AUTOSAR XML (schema 4-0-3)
standard types defined: UInt32, UInt8
package /AUTOSAR_Platform/DataConstrs
  range DC_UInt8: raw 0..255
package /PATAC/MSM/ComponentTypes
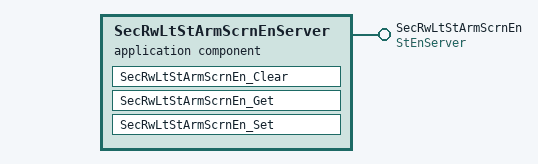
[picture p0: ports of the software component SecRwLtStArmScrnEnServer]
  application sw component type SecRwLtStArmScrnEnServer
    provide port SecRwLtStArmScrnEn: provided-com-specs=[{operation=Clear, queue-length=1}, {operation=Get, queue-length=1}, {operation=Set, queue-length=1}], provided-interface=StEnServer
    behavior SecRwLtStArmScrnEnServer_InternalBehavior
      operation invoked event OIT_SecRwLtStArmScrnEn_Clear_SecRwLtStArmScrnEn_Clear: start-on-event=SecRwLtStArmScrnEn_Clear, operation=SecRwLtStArmScrnEn.Clear
      operation invoked event OIT_SecRwLtStArmScrnEn_Get_SecRwLtStArmScrnEn_Get: start-on-event=SecRwLtStArmScrnEn_Get, operation=SecRwLtStArmScrnEn.Get
      operation invoked event OIT_SecRwLtStArmScrnEn_Set_SecRwLtStArmScrnEn_Set: start-on-event=SecRwLtStArmScrnEn_Set, operation=SecRwLtStArmScrnEn.Set
      runnable SecRwLtStArmScrnEn_Clear
      runnable SecRwLtStArmScrnEn_Get
      runnable SecRwLtStArmScrnEn_Set
  swc implementation SecRwLtStArmScrnEnServer_Implementation: behavior=SecRwLtStArmScrnEnServer_InternalBehavior
    code-descriptors:
      code Default: artifact-descriptors=autosar-engineering-object={short-label=Default, category=SWSRC}
package /PATAC/MSM/ModeAdjust/PortInterface
  client server interface StEnServer
    operation Clear
      arg data: type=UInt8, direction=IN, server-argument-impl-policy=USE-ARGUMENT-TYPE
    operation Get
      arg data: type=UInt32, direction=OUT, server-argument-impl-policy=USE-ARGUMENT-TYPE
    operation Set
      arg data: type=UInt8, direction=IN, server-argument-impl-policy=USE-ARGUMENT-TYPE
